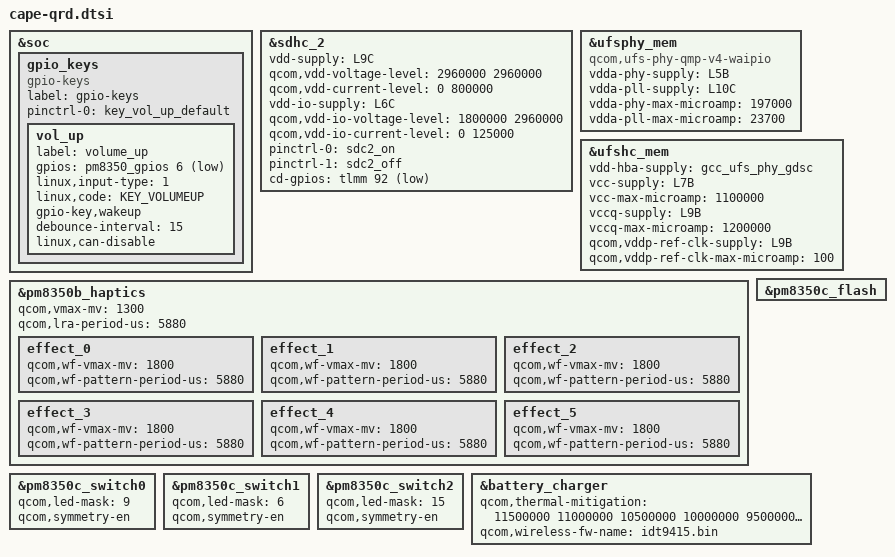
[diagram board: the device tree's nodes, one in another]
#include <dt-bindings/gpio/gpio.h>
#include <dt-bindings/input/input.h>
#include "cape-pmic-overlay.dtsi"
#include "waipio-thermal-overlay.dtsi"

&soc {
	gpio_keys {
		compatible = "gpio-keys";
		label = "gpio-keys";

		pinctrl-names = "default";
		pinctrl-0 = <&key_vol_up_default>;

		vol_up {
			label = "volume_up";
			gpios = <&pm8350_gpios 6 GPIO_ACTIVE_LOW>;
			linux,input-type = <1>;
			linux,code = <KEY_VOLUMEUP>;
			gpio-key,wakeup;
			debounce-interval = <15>;
			linux,can-disable;
		};
	};
};

&sdhc_2 {
	status = "ok";
	vdd-supply = <&L9C>;
	qcom,vdd-voltage-level = <2960000 2960000>;
	qcom,vdd-current-level = <0 800000>;

	vdd-io-supply = <&L6C>;
	qcom,vdd-io-voltage-level = <1800000 2960000>;
	qcom,vdd-io-current-level = <0 125000>;

	pinctrl-names = "default", "sleep";
	pinctrl-0 = <&sdc2_on>;
	pinctrl-1 = <&sdc2_off>;

	cd-gpios = <&tlmm 92 GPIO_ACTIVE_LOW>;
};

&ufsphy_mem {
	compatible = "qcom,ufs-phy-qmp-v4-waipio";

	vdda-phy-supply = <&L5B>;
	vdda-pll-supply = <&L10C>;
	vdda-phy-max-microamp = <197000>;
	vdda-pll-max-microamp = <23700>;

	status = "ok";
};

&ufshc_mem {
	vdd-hba-supply = <&gcc_ufs_phy_gdsc>;

	vcc-supply = <&L7B>;
	vcc-max-microamp = <1100000>;

	vccq-supply = <&L9B>;
	vccq-max-microamp = <1200000>;

	qcom,vddp-ref-clk-supply = <&L9B>;
	qcom,vddp-ref-clk-max-microamp = <100>;

	status = "ok";
};

&pm8350b_haptics {
	qcom,vmax-mv = <1300>;
	qcom,lra-period-us = <5880>;
	status = "ok";

	effect_0 {
		/* CLICK */
		qcom,wf-vmax-mv = <1800>;
		qcom,wf-pattern-period-us = <5880>;
	};

	effect_1 {
		/* DOUBLE_CLICK */
		qcom,wf-vmax-mv = <1800>;
		qcom,wf-pattern-period-us = <5880>;
	};

	effect_2 {
		/* TICK */
		qcom,wf-vmax-mv = <1800>;
		qcom,wf-pattern-period-us = <5880>;
	};

	effect_3 {
		/* THUD */
		qcom,wf-vmax-mv = <1800>;
		qcom,wf-pattern-period-us = <5880>;
	};

	effect_4 {
		/* POP */
		qcom,wf-vmax-mv = <1800>;
		qcom,wf-pattern-period-us = <5880>;
	};

	effect_5 {
		/* HEAVY CLICK */
		qcom,wf-vmax-mv = <1800>;
		qcom,wf-pattern-period-us = <5880>;
	};
};

&pm8350c_switch0 {
	qcom,led-mask = <9>; /* Channels 1 & 4 */
	qcom,symmetry-en;
};

&pm8350c_switch1 {
	qcom,led-mask = <6>; /* Channels 2 & 3 */
	qcom,symmetry-en;
};

&pm8350c_switch2 {
	qcom,led-mask = <15>; /* All Channels */
	qcom,symmetry-en;
};

&pm8350c_flash {
	status = "ok";
};

&battery_charger {
	qcom,thermal-mitigation = <11500000 11000000 10500000 10000000 9500000
				9000000 8500000 8000000 7500000 7000000 6500000
				6000000 5500000 5000000 4500000 4000000 3500000
				3000000 2500000 2000000 1500000 1000000 500000>;
	qcom,wireless-fw-name = "idt9415.bin";
};
